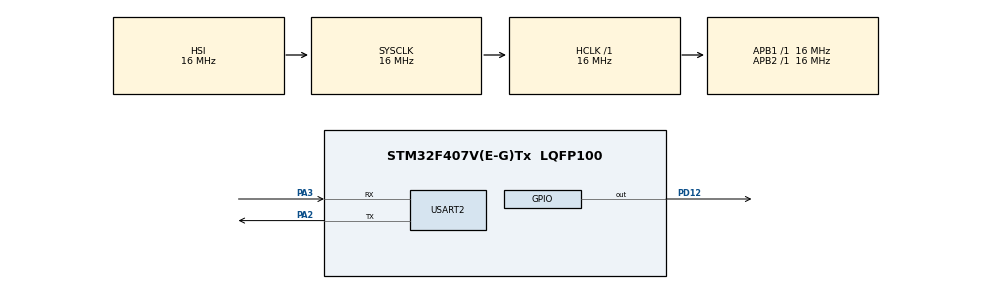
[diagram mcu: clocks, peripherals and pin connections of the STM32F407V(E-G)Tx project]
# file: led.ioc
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FREERTOS.Tasks01=defaultTask,24,128,StartDefaultTask,Default,NULL,Dynamic,NULL,NULL;uartTask,24,128,StartUartTask,Default,NULL,Dynamic,NULL,NULL;ledTask,8,128,StartLedTask,Default,NULL,Dynamic,NULL,NULL
FREERTOS.configMAX_TASK_NAME_LEN=20
FREERTOS.configUSE_OS2_THREAD_FLAGS=1
Mcu.Family=STM32F4
Mcu.Name=STM32F407V(E-G)Tx
Mcu.Package=LQFP100
NVIC.PriorityGroup=NVIC_PRIORITYGROUP_4
NVIC.TIM6_DAC_IRQn=true\:15\:0\:false\:false\:true\:false\:false\:true\:true
NVIC.TimeBase=TIM6_DAC_IRQn
NVIC.TimeBaseIP=TIM6
NVIC.USART2_IRQn=true\:5\:0\:false\:false\:true\:true\:true\:true\:true
PA2.Mode=Asynchronous
PA2.Signal=USART2_TX
PA3.Mode=Asynchronous
PA3.Signal=USART2_RX
PD12.Signal=GPIO_Output
ProjectManager.HeapSize=0x200
ProjectManager.StackSize=0x400
ProjectManager.TargetToolchain=EWARM V8.50
RCC.AHBFreq_Value=16000000
RCC.APB1Freq_Value=16000000
RCC.APB2Freq_Value=16000000
RCC.CortexFreq_Value=16000000
RCC.HSE_VALUE=25000000
RCC.HSI_VALUE=16000000
RCC.LSE_VALUE=32768
RCC.SYSCLKFreq_VALUE=16000000
RCC.VCOOutputFreq_Value=192000000
USART2.VirtualMode=VM_ASYNC
VP_FREERTOS_VS_CMSIS_V2.Mode=CMSIS_V2
VP_SYS_VS_tim6.Mode=TIM6
board=custom

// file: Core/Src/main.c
/* USER CODE BEGIN Header */
/**
  ******************************************************************************
  * @file           : main.c
  * @brief          : Main program body
  ******************************************************************************
  * @attention
  *
  * Copyright (c) 2025 STMicroelectronics.
  * All rights reserved.
  *
  * This software is licensed under terms that can be found in the LICENSE file
  * in the root directory of this software component.
  * If no LICENSE file comes with this software, it is provided AS-IS.
  *
  ******************************************************************************
  */
/* USER CODE END Header */
#include "main.h"
#include "cmsis_os.h"

UART_HandleTypeDef huart2;

/* Definitions for defaultTask */
//osThreadId_t defaultTaskHandle;
//const osThreadAttr_t defaultTask_attributes = {
  //.name = "defaultTask",
 // .stack_size = 128 * 4,
 // .priority = (osPriority_t) osPriorityNormal,
//};
/* Definitions for uartTask */
osThreadId_t uartTaskHandle;
const osThreadAttr_t uartTask_attributes = {
  .name = "uartTask",
  .stack_size = 128 * 4,
  .priority = (osPriority_t) osPriorityNormal,
};
/* Definitions for ledTask */
osThreadId_t ledTaskHandle;
const osThreadAttr_t ledTask_attributes = {
  .name = "ledTask",
  .stack_size = 128 * 4,
  .priority = (osPriority_t) osPriorityLow,
};
/* USER CODE BEGIN PV */
uint8_t data[] = "Hello, FreeRTOS!\r\n";

/* USER CODE END PV */

void SystemClock_Config(void);
static void MX_GPIO_Init(void);
static void MX_USART2_UART_Init(void);
//void StartDefaultTask(void *argument);
void StartUartTask(void *argument);
void StartLedTask(void *argument);

int main(void)
{

  /* MCU Configuration--------------------------------------------------------*/

  /* Reset of all peripherals, Initializes the Flash interface and the Systick. */
  HAL_Init();

  /* Configure the system clock */
  SystemClock_Config();

  /* Initialize all configured peripherals */
  MX_GPIO_Init();
  MX_USART2_UART_Init();

  /* Init scheduler */
  osKernelInitialize();

  /* Create the thread(s) */
  /* creation of defaultTask */
  //defaultTaskHandle = osThreadNew(StartDefaultTask, NULL, &defaultTask_attributes);

  /* creation of uartTask */
  uartTaskHandle = osThreadNew(StartUartTask, NULL, &uartTask_attributes);

  /* creation of ledTask */
  ledTaskHandle = osThreadNew(StartLedTask, NULL, &ledTask_attributes);

  /* Start scheduler */
  osKernelStart();

  /* We should never get here as control is now taken by the scheduler */

  /* Infinite loop */
  while (1)
  {

  }
}

void SystemClock_Config(void)
{
  RCC_OscInitTypeDef RCC_OscInitStruct = {0};
  RCC_ClkInitTypeDef RCC_ClkInitStruct = {0};

  /** Configure the main internal regulator output voltage
  */
  __HAL_RCC_PWR_CLK_ENABLE();
  __HAL_PWR_VOLTAGESCALING_CONFIG(PWR_REGULATOR_VOLTAGE_SCALE1);

  /** Initializes the RCC Oscillators according to the specified parameters
  * in the RCC_OscInitTypeDef structure.
  */
  RCC_OscInitStruct.OscillatorType = RCC_OSCILLATORTYPE_HSI;
  RCC_OscInitStruct.HSIState = RCC_HSI_ON;
  RCC_OscInitStruct.HSICalibrationValue = RCC_HSICALIBRATION_DEFAULT;
  RCC_OscInitStruct.PLL.PLLState = RCC_PLL_NONE;
  if (HAL_RCC_OscConfig(&RCC_OscInitStruct) != HAL_OK)
  {
    Error_Handler();
  }

  /** Initializes the CPU, AHB and APB buses clocks
  */
  RCC_ClkInitStruct.ClockType = RCC_CLOCKTYPE_HCLK|RCC_CLOCKTYPE_SYSCLK
                              |RCC_CLOCKTYPE_PCLK1|RCC_CLOCKTYPE_PCLK2;
  RCC_ClkInitStruct.SYSCLKSource = RCC_SYSCLKSOURCE_HSI;
  RCC_ClkInitStruct.AHBCLKDivider = RCC_SYSCLK_DIV1;
  RCC_ClkInitStruct.APB1CLKDivider = RCC_HCLK_DIV1;
  RCC_ClkInitStruct.APB2CLKDivider = RCC_HCLK_DIV1;

  if (HAL_RCC_ClockConfig(&RCC_ClkInitStruct, FLASH_LATENCY_0) != HAL_OK)
  {
    Error_Handler();
  }
}

static void MX_USART2_UART_Init(void)
{

  huart2.Instance = USART2;
  huart2.Init.BaudRate = 115200;
  huart2.Init.WordLength = UART_WORDLENGTH_8B;
  huart2.Init.StopBits = UART_STOPBITS_1;
  huart2.Init.Parity = UART_PARITY_NONE;
  huart2.Init.Mode = UART_MODE_TX_RX;
  huart2.Init.HwFlowCtl = UART_HWCONTROL_NONE;
  huart2.Init.OverSampling = UART_OVERSAMPLING_16;
  if (HAL_UART_Init(&huart2) != HAL_OK)
  {
    Error_Handler();
  }

}

static void MX_GPIO_Init(void)
{
  GPIO_InitTypeDef GPIO_InitStruct = {0};

  /* GPIO Ports Clock Enable */
  __HAL_RCC_GPIOA_CLK_ENABLE();
  __HAL_RCC_GPIOD_CLK_ENABLE();

  /*Configure GPIO pin Output Level */
  HAL_GPIO_WritePin(GPIOD, GPIO_PIN_12, GPIO_PIN_RESET);

  /*Configure GPIO pin : PD12 */
  GPIO_InitStruct.Pin = GPIO_PIN_12;
  GPIO_InitStruct.Mode = GPIO_MODE_OUTPUT_PP;
  GPIO_InitStruct.Pull = GPIO_NOPULL;
  GPIO_InitStruct.Speed = GPIO_SPEED_FREQ_LOW;
  HAL_GPIO_Init(GPIOD, &GPIO_InitStruct);

}

//void StartDefaultTask(void *argument)
//{
  /* USER CODE BEGIN 5 */
  /* Infinite loop */
  //for(;;)
  //{
    //osDelay(1);
  //}
  /* USER CODE END 5 */
//}

void StartUartTask(void *argument)
{
  /* USER CODE BEGIN StartUartTask */
  /* Infinite loop */
  for(;;)
  {
    HAL_UART_Transmit(&huart2, data, sizeof(data) - 1, 100);
    osDelay(1000);
  }
  /* USER CODE END StartUartTask */
}

void StartLedTask(void *argument)
{
  /* USER CODE BEGIN StartLedTask */
  /* Infinite loop */
  for(;;)
  {
    HAL_GPIO_TogglePin(GPIOD, GPIO_PIN_12);
    osDelay(1000);
  }
  /* USER CODE END StartLedTask */
}

void HAL_TIM_PeriodElapsedCallback(TIM_HandleTypeDef *htim)
{
  if (htim->Instance == TIM6) {
    HAL_IncTick();
  }
}

void Error_Handler(void)
{
  __disable_irq();
  while (1)
  {
  }
}
